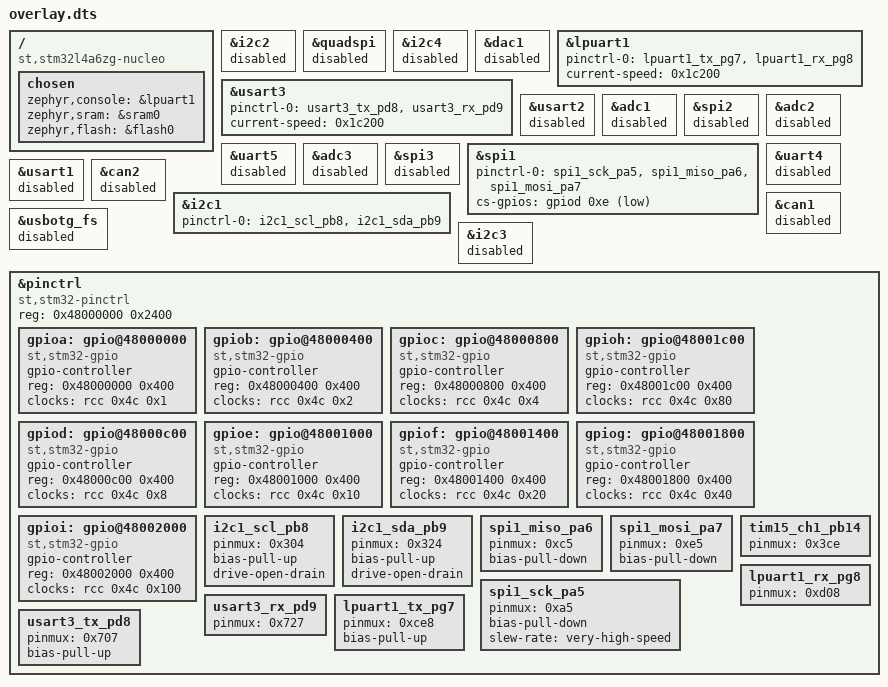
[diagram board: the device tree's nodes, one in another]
/ {
	compatible = "st,stm32l4a6zg-nucleo";
	chosen {
		zephyr,console = &lpuart1;
		zephyr,sram = &sram0;
		zephyr,flash = &flash0;
	};
};
&i2c2{
	status = "disabled";
};
&quadspi{
	status = "disabled";
};
&i2c4{
	status = "disabled";
};
&dac1{
	status = "disabled";
};
&lpuart1{
	status = "okay";
	pinctrl-0 = < &lpuart1_tx_pg7 &lpuart1_rx_pg8 >;
	pinctrl-names = "default";
	current-speed = < 0x1c200 >;
};
&usart3{
	status = "okay";
	pinctrl-0 = < &usart3_tx_pd8 &usart3_rx_pd9 >;
	pinctrl-names = "default";
	current-speed = < 0x1c200 >;
};
&usart2{
	status = "disabled";
};
&adc1{
	status = "disabled";
};
&spi2{
	status = "disabled";
};
&adc2{
	status = "disabled";
};
&uart5{
	status = "disabled";
};
&adc3{
	status = "disabled";
};
&spi3{
	status = "disabled";
};
&spi1{
	status = "okay";
	pinctrl-0 = < &spi1_sck_pa5 &spi1_miso_pa6 &spi1_mosi_pa7 >;
	pinctrl-names = "default";
	cs-gpios = < &gpiod 0xe 0x11 >;
};
&uart4{
	status = "disabled";
};
&usart1{
	status = "disabled";
};
&can2{
	status = "disabled";
};
&i2c1{
	status = "okay";
	pinctrl-0 = < &i2c1_scl_pb8 &i2c1_sda_pb9 >;
	pinctrl-names = "default";
};
&can1{
	status = "disabled";
};
&usbotg_fs{
	status = "disabled";
};
&i2c3{
	status = "disabled";
};
&pinctrl{
	compatible = "st,stm32-pinctrl";
	#address-cells = < 0x1 >;
	#size-cells = < 0x1 >;
	reg = < 0x48000000 0x2400 >;
	gpioa: gpio@48000000 {
		compatible = "st,stm32-gpio";
		gpio-controller;
		#gpio-cells = < 0x2 >;
		reg = < 0x48000000 0x400 >;
		clocks = < &rcc 0x4c 0x1 >;
	};
	gpiob: gpio@48000400 {
		compatible = "st,stm32-gpio";
		gpio-controller;
		#gpio-cells = < 0x2 >;
		reg = < 0x48000400 0x400 >;
		clocks = < &rcc 0x4c 0x2 >;
	};
	gpioc: gpio@48000800 {
		compatible = "st,stm32-gpio";
		gpio-controller;
		#gpio-cells = < 0x2 >;
		reg = < 0x48000800 0x400 >;
		clocks = < &rcc 0x4c 0x4 >;
	};
	gpioh: gpio@48001c00 {
		compatible = "st,stm32-gpio";
		gpio-controller;
		#gpio-cells = < 0x2 >;
		reg = < 0x48001c00 0x400 >;
		clocks = < &rcc 0x4c 0x80 >;
	};
	gpiod: gpio@48000c00 {
		compatible = "st,stm32-gpio";
		gpio-controller;
		#gpio-cells = < 0x2 >;
		reg = < 0x48000c00 0x400 >;
		clocks = < &rcc 0x4c 0x8 >;
	};
	gpioe: gpio@48001000 {
		compatible = "st,stm32-gpio";
		gpio-controller;
		#gpio-cells = < 0x2 >;
		reg = < 0x48001000 0x400 >;
		clocks = < &rcc 0x4c 0x10 >;
	};
	gpiof: gpio@48001400 {
		compatible = "st,stm32-gpio";
		gpio-controller;
		#gpio-cells = < 0x2 >;
		reg = < 0x48001400 0x400 >;
		clocks = < &rcc 0x4c 0x20 >;
	};
	gpiog: gpio@48001800 {
		compatible = "st,stm32-gpio";
		gpio-controller;
		#gpio-cells = < 0x2 >;
		reg = < 0x48001800 0x400 >;
		clocks = < &rcc 0x4c 0x40 >;
	};
	gpioi: gpio@48002000 {
		compatible = "st,stm32-gpio";
		gpio-controller;
		#gpio-cells = < 0x2 >;
		reg = < 0x48002000 0x400 >;
		clocks = < &rcc 0x4c 0x100 >;
	};
	i2c1_scl_pb8: i2c1_scl_pb8 {
		pinmux = < 0x304 >;
		bias-pull-up;
		drive-open-drain;
	};
	i2c1_sda_pb9: i2c1_sda_pb9 {
		pinmux = < 0x324 >;
		bias-pull-up;
		drive-open-drain;
	};
	spi1_miso_pa6: spi1_miso_pa6 {
		pinmux = < 0xc5 >;
		bias-pull-down;
	};
	spi1_mosi_pa7: spi1_mosi_pa7 {
		pinmux = < 0xe5 >;
		bias-pull-down;
	};
	spi1_sck_pa5: spi1_sck_pa5 {
		pinmux = < 0xa5 >;
		bias-pull-down;
		slew-rate = "very-high-speed";
	};
	tim15_ch1_pb14: tim15_ch1_pb14 {
		pinmux = < 0x3ce >;
	};
	lpuart1_rx_pg8: lpuart1_rx_pg8 {
		pinmux = < 0xd08 >;
	};
	usart3_rx_pd9: usart3_rx_pd9 {
		pinmux = < 0x727 >;
	};
	lpuart1_tx_pg7: lpuart1_tx_pg7 {
		pinmux = < 0xce8 >;
		bias-pull-up;
	};
	usart3_tx_pd8: usart3_tx_pd8 {
		pinmux = < 0x707 >;
		bias-pull-up;
	};
};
